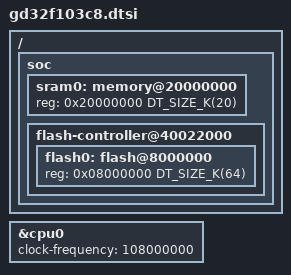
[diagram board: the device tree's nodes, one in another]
/*
 * Copyright (c) 2025 liangyq <liangyongqincn@gmail.com>
 *
 * SPDX-License-Identifier: Apache-2.0
 */

#include <gd/gd32f10x/gd32f10x.dtsi>
#include <mem.h>

/ {
    soc {
        sram0: memory@20000000 {
            reg = <0x20000000 DT_SIZE_K(20)>;
        };

        flash-controller@40022000 {
                flash0: flash@8000000 {
                    reg = <0x08000000 DT_SIZE_K(64)>;
                };
	    };
    };
};

&cpu0 {
	clock-frequency = <108000000>;
};
